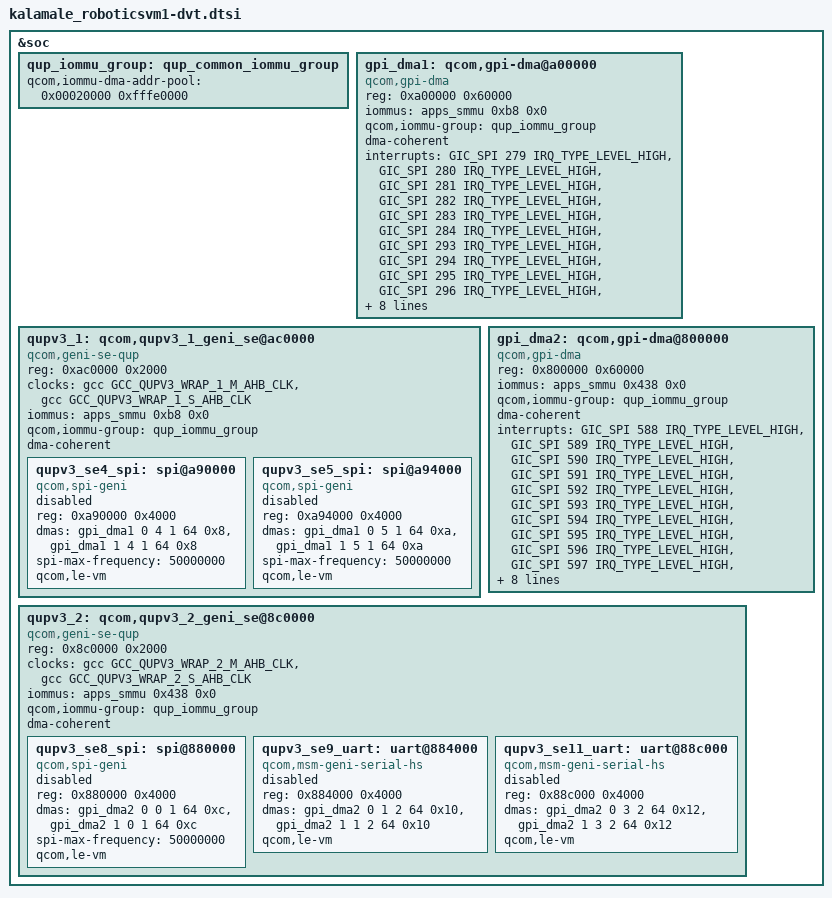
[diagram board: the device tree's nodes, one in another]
&soc {

       /*
	* QUPv3 Instances
	* QUP1 : SE4
	* QUP1 : SE5
	* QUP2 : SE0
	* QUP2 : SE1
	* QUP2 : SE3
	*/
	qup_iommu_group: qup_common_iommu_group {
			qcom,iommu-dma-addr-pool = <0x00020000 0xfffe0000>;
	};

	/* GPI Instance */
	gpi_dma1: qcom,gpi-dma@a00000  {
		compatible = "qcom,gpi-dma";
		#dma-cells = <5>;
		reg = <0xa00000  0x60000>;
		reg-names = "gpi-top";
		iommus = <&apps_smmu 0xb8 0x0>;
		qcom,iommu-group = <&qup_iommu_group>;
		dma-coherent;
		interrupts = <GIC_SPI 279 IRQ_TYPE_LEVEL_HIGH>,
			<GIC_SPI 280 IRQ_TYPE_LEVEL_HIGH>,
			<GIC_SPI 281 IRQ_TYPE_LEVEL_HIGH>,
			<GIC_SPI 282 IRQ_TYPE_LEVEL_HIGH>,
			<GIC_SPI 283 IRQ_TYPE_LEVEL_HIGH>,
			<GIC_SPI 284 IRQ_TYPE_LEVEL_HIGH>,
			<GIC_SPI 293 IRQ_TYPE_LEVEL_HIGH>,
			<GIC_SPI 294 IRQ_TYPE_LEVEL_HIGH>,
			<GIC_SPI 295 IRQ_TYPE_LEVEL_HIGH>,
			<GIC_SPI 296 IRQ_TYPE_LEVEL_HIGH>,
			<GIC_SPI 297 IRQ_TYPE_LEVEL_HIGH>,
			<GIC_SPI 298 IRQ_TYPE_LEVEL_HIGH>;
		qcom,max-num-gpii = <12>;
		qcom,gpii-mask = <0x0>;
		qcom,static-gpii-mask = <0x18>;
		qcom,ev-factor = <1>;
		qcom,gpi-ee-offset = <0x10000>;
		qcom,le-vm;
		status = "ok";
	};

	/* QUPv3_1 Wrapper instance */
	qupv3_1: qcom,qupv3_1_geni_se@ac0000 {
		compatible = "qcom,geni-se-qup";
		reg = <0xac0000 0x2000>;
		#address-cells = <1>;
		#size-cells = <1>;
		clock-names = "m-ahb", "s-ahb";
		clocks = <&gcc GCC_QUPV3_WRAP_1_M_AHB_CLK>,
			<&gcc GCC_QUPV3_WRAP_1_S_AHB_CLK>;
		iommus = <&apps_smmu 0xb8 0x0>;
		qcom,iommu-group = <&qup_iommu_group>;
		dma-coherent;
		ranges;
		status = "ok";

		qupv3_se4_spi: spi@a90000 {
			compatible = "qcom,spi-geni";
			reg = <0xa90000 0x4000>;
			reg-names = "se_phys";
			#address-cells = <1>;
			#size-cells = <0>;
			dmas = <&gpi_dma1 0 4 1 64 0x8>,
				<&gpi_dma1 1 4 1 64 0x8>;
			dma-names = "tx", "rx";
			spi-max-frequency = <50000000>;
			qcom,le-vm;
			status = "disabled";
		};

		qupv3_se5_spi: spi@a94000 {
			compatible = "qcom,spi-geni";
			reg = <0xa94000 0x4000>;
			reg-names = "se_phys";
			#address-cells = <1>;
			#size-cells = <0>;
			dmas = <&gpi_dma1 0 5 1 64 0xa>,
				<&gpi_dma1 1 5 1 64 0xa>;
			dma-names = "tx", "rx";
			spi-max-frequency = <50000000>;
			qcom,le-vm;
			status = "disabled";
		};
	};

	/* GPI Instance */
	gpi_dma2: qcom,gpi-dma@800000  {
		compatible = "qcom,gpi-dma";
		#dma-cells = <5>;
		reg = <0x800000 0x60000>;
		reg-names = "gpi-top";
		iommus = <&apps_smmu 0x438 0x0>;
		qcom,iommu-group = <&qup_iommu_group>;
		dma-coherent;
		interrupts = <GIC_SPI 588 IRQ_TYPE_LEVEL_HIGH>,
			<GIC_SPI 589 IRQ_TYPE_LEVEL_HIGH>,
			<GIC_SPI 590 IRQ_TYPE_LEVEL_HIGH>,
			<GIC_SPI 591 IRQ_TYPE_LEVEL_HIGH>,
			<GIC_SPI 592 IRQ_TYPE_LEVEL_HIGH>,
			<GIC_SPI 593 IRQ_TYPE_LEVEL_HIGH>,
			<GIC_SPI 594 IRQ_TYPE_LEVEL_HIGH>,
			<GIC_SPI 595 IRQ_TYPE_LEVEL_HIGH>,
			<GIC_SPI 596 IRQ_TYPE_LEVEL_HIGH>,
			<GIC_SPI 597 IRQ_TYPE_LEVEL_HIGH>,
			<GIC_SPI 598 IRQ_TYPE_LEVEL_HIGH>,
			<GIC_SPI 599 IRQ_TYPE_LEVEL_HIGH>;
		qcom,max-num-gpii = <12>;
		qcom,gpii-mask = <0x0>;
		qcom,static-gpii-mask = <0x1A0>;
		qcom,ev-factor = <1>;
		qcom,gpi-ee-offset = <0x10000>;
		qcom,le-vm;
		status = "ok";
	};

	/* QUPv3_2 Wrapper Instance */
	qupv3_2: qcom,qupv3_2_geni_se@8c0000 {
		compatible = "qcom,geni-se-qup";
		reg = <0x8c0000 0x2000>;
		#address-cells = <1>;
		#size-cells = <1>;
		clock-names = "m-ahb", "s-ahb";
		clocks = <&gcc GCC_QUPV3_WRAP_2_M_AHB_CLK>,
			<&gcc GCC_QUPV3_WRAP_2_S_AHB_CLK>;
		iommus = <&apps_smmu 0x438 0x0>;
		qcom,iommu-group = <&qup_iommu_group>;
		dma-coherent;
		ranges;
		status = "ok";

		qupv3_se8_spi: spi@880000 {
			compatible = "qcom,spi-geni";
			reg = <0x880000 0x4000>;
			reg-names = "se_phys";
			#address-cells = <1>;
			#size-cells = <0>;
			dmas = <&gpi_dma2 0 0 1 64 0xc>,
				<&gpi_dma2 1 0 1 64 0xc>;
			dma-names = "tx", "rx";
			spi-max-frequency = <50000000>;
			qcom,le-vm;
			status = "disabled";
		};

		qupv3_se9_uart: uart@884000 {
			compatible = "qcom,msm-geni-serial-hs";
			reg = <0x884000 0x4000>;
			reg-names = "se_phys";
			dmas = <&gpi_dma2 0 1 2 64 0x10>,
				<&gpi_dma2 1 1 2 64 0x10>;
			dma-names = "tx", "rx";
			qcom,le-vm;
			status = "disabled";
		};

		qupv3_se11_uart: uart@88c000 {
			compatible = "qcom,msm-geni-serial-hs";
			reg = <0x88c000 0x4000>;
			reg-names = "se_phys";
			dmas = <&gpi_dma2 0 3 2 64 0x12>,
				<&gpi_dma2 1 3 2 64 0x12>;
			dma-names = "tx", "rx";
			qcom,le-vm;
			status = "disabled";
		};
	};
};

#include "msm-arm-smmu-kalama-vm.dtsi"
